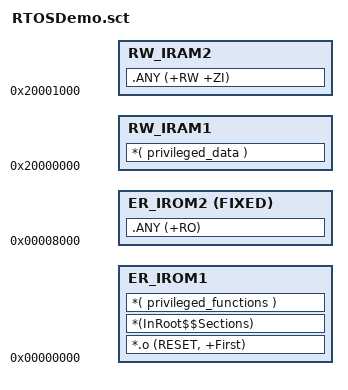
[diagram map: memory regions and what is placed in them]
; *************************************************************
; *** Scatter-Loading Description File generated by uVision ***
; *************************************************************


LR_IROM1 0x00000000  {    ; load region size_region
  ER_IROM1 0x00000000  {  ; load address = execution address
   *.o (RESET, +First)
   *(InRoot$$Sections)
   *( privileged_functions )
  }
  ER_IROM2 0x8000 FIXED {
    .ANY (+RO)
  }
  RW_IRAM1 0x20000000  {  ; RW data
   *( privileged_data )
  }
  RW_IRAM2 0x20001000 {  ; RW data
   .ANY (+RW +ZI)
  }
}


